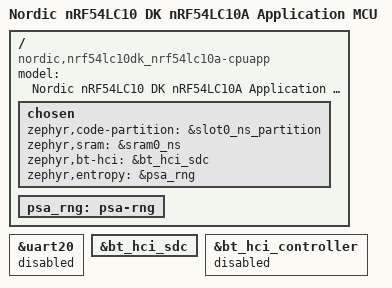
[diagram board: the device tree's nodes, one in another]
/*
 * Copyright (c) 2026 Nordic Semiconductor ASA
 *
 * SPDX-License-Identifier: LicenseRef-Nordic-5-Clause
 */

/dts-v1/;

#define USE_NON_SECURE_ADDRESS_MAP 1

#include "nrf54lc10a_cpuapp_common.dtsi"

/ {
	compatible = "nordic,nrf54lc10dk_nrf54lc10a-cpuapp";
	model = "Nordic nRF54LC10 DK nRF54LC10A Application MCU";

	chosen {
		zephyr,code-partition = &slot0_ns_partition;
		zephyr,sram = &sram0_ns;
		zephyr,bt-hci = &bt_hci_sdc;
		zephyr,entropy = &psa_rng;
	};

	psa_rng: psa-rng {
		status = "okay";
	};
};

&uart20 {
	/* Disable so that TF-M can use this UART */
	status = "disabled";
};

&bt_hci_sdc {
	status = "okay";
};

&bt_hci_controller {
	status = "disabled";
};

/* Include default memory partition configuration file */
#include <nordic/nrf54lc10a_cpuapp_ns_partition.dtsi>
